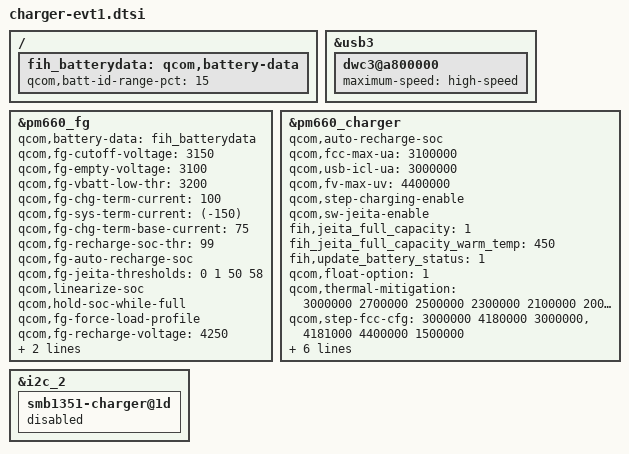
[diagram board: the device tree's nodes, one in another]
/ {
	/delete-node/ qcom,battery-data;
	fih_batterydata: qcom,battery-data {
		qcom,batt-id-range-pct = <15>;
		#include "fg-gen3-batterydata-scud-2750mah-200k-sat2.dtsi"
		#include "fg-gen3-batterydata-scud-3000mah-100k-sat.dtsi"
	};
};

&usb3 {
	dwc3@a800000 {
		maximum-speed = "high-speed";
	};
};

&pm660_fg {
	qcom,battery-data = <&fih_batterydata>;
	qcom,fg-cutoff-voltage = <3150>;
	qcom,fg-empty-voltage = <3100>;
	qcom,fg-vbatt-low-thr = <3200>;
	qcom,fg-chg-term-current = <100>;	/* 100mA > 0.02C */
	qcom,fg-sys-term-current = <(-150)>;	/* 100mA + 25mA */
	qcom,fg-chg-term-base-current = <75>;	/* 100mA - 25mA */
	qcom,fg-recharge-soc-thr = <99>;
       qcom,fg-auto-recharge-soc;
	qcom,fg-jeita-thresholds = <0 1 50 58>;
	qcom,linearize-soc;
	qcom,hold-soc-while-full;
	qcom,fg-force-load-profile;
	qcom,fg-recharge-voltage = <4250>;
	qcom,battery-thermal-coefficients = [A3 50 ff];
	qcom,fg-rsense-sel = <0>;
};

&pm660_charger {
	/delete-property/ qcom,batteryless-platform;
	qcom,auto-recharge-soc;
	qcom,fcc-max-ua = <3100000>;
	qcom,usb-icl-ua = <3000000>;
	qcom,fv-max-uv = <4400000>;
	/delete-property/ qcom,wipower-max-uw;
	qcom,step-charging-enable;
	qcom,sw-jeita-enable;
	fih,jeita_full_capacity = <1>;
	fih_jeita_full_capacity_warm_temp = <450>;
	fih,update_battery_status = <1>;
	qcom,float-option = <1>;
	/delete-property/ qcom,hvdcp-disable;
	qcom,thermal-mitigation = <3000000 2700000 2500000 2300000 2100000 2000000
		1600000 1200000 1000000 700000 600000 500000 100000 0>;
/* VBAT_LOW	VBAT_HIGH	FCC */
	qcom,step-fcc-cfg = <3000000 4180000 3000000>,
					<4181000 4400000 1500000>;
/* TEMP_LOW	TEMP_HIGH	FCC */
	qcom,jeita-fcc-cfg = <0 157 600000>,
					<158 440 3000000>,
					<441 550 900000>;
/* TEMP_LOW	TEMP_HIGH	FV */
	qcom,jeita-fv-cfg = <0 157 4400000>,
					<158 440 4400000>,
					<441 550 4100000>;
	qcom,step-fcc-hysteresis = <20000>;
	qcom,jeita-fcc-fv-hysteresis = <6>;
};

&i2c_2 {
	smb1351-charger@1d {
		status = "disabled";
	};
};
